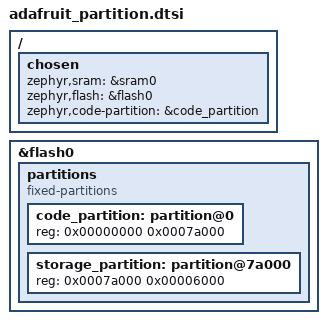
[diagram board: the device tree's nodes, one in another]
/*
 * Copyright (c) 2024 Jacob Winther
 *
 * SPDX-License-Identifier: Apache-2.0
 */

/ {
	chosen {
		zephyr,sram = &sram0;
		zephyr,flash = &flash0;
		zephyr,code-partition = &code_partition;
	};
};

&flash0 {
    partitions {
        compatible = "fixed-partitions";
        #address-cells = <1>;
        #size-cells = <1>;

        code_partition: partition@0 {
            reg = <0x00000000 0x0007a000>;
        };

        /* Set 24KiB of storage at the end of the 256KiB of flash */
        storage_partition: partition@7a000 {
            reg = <0x0007a000 0x00006000>;
        };
  };
};
